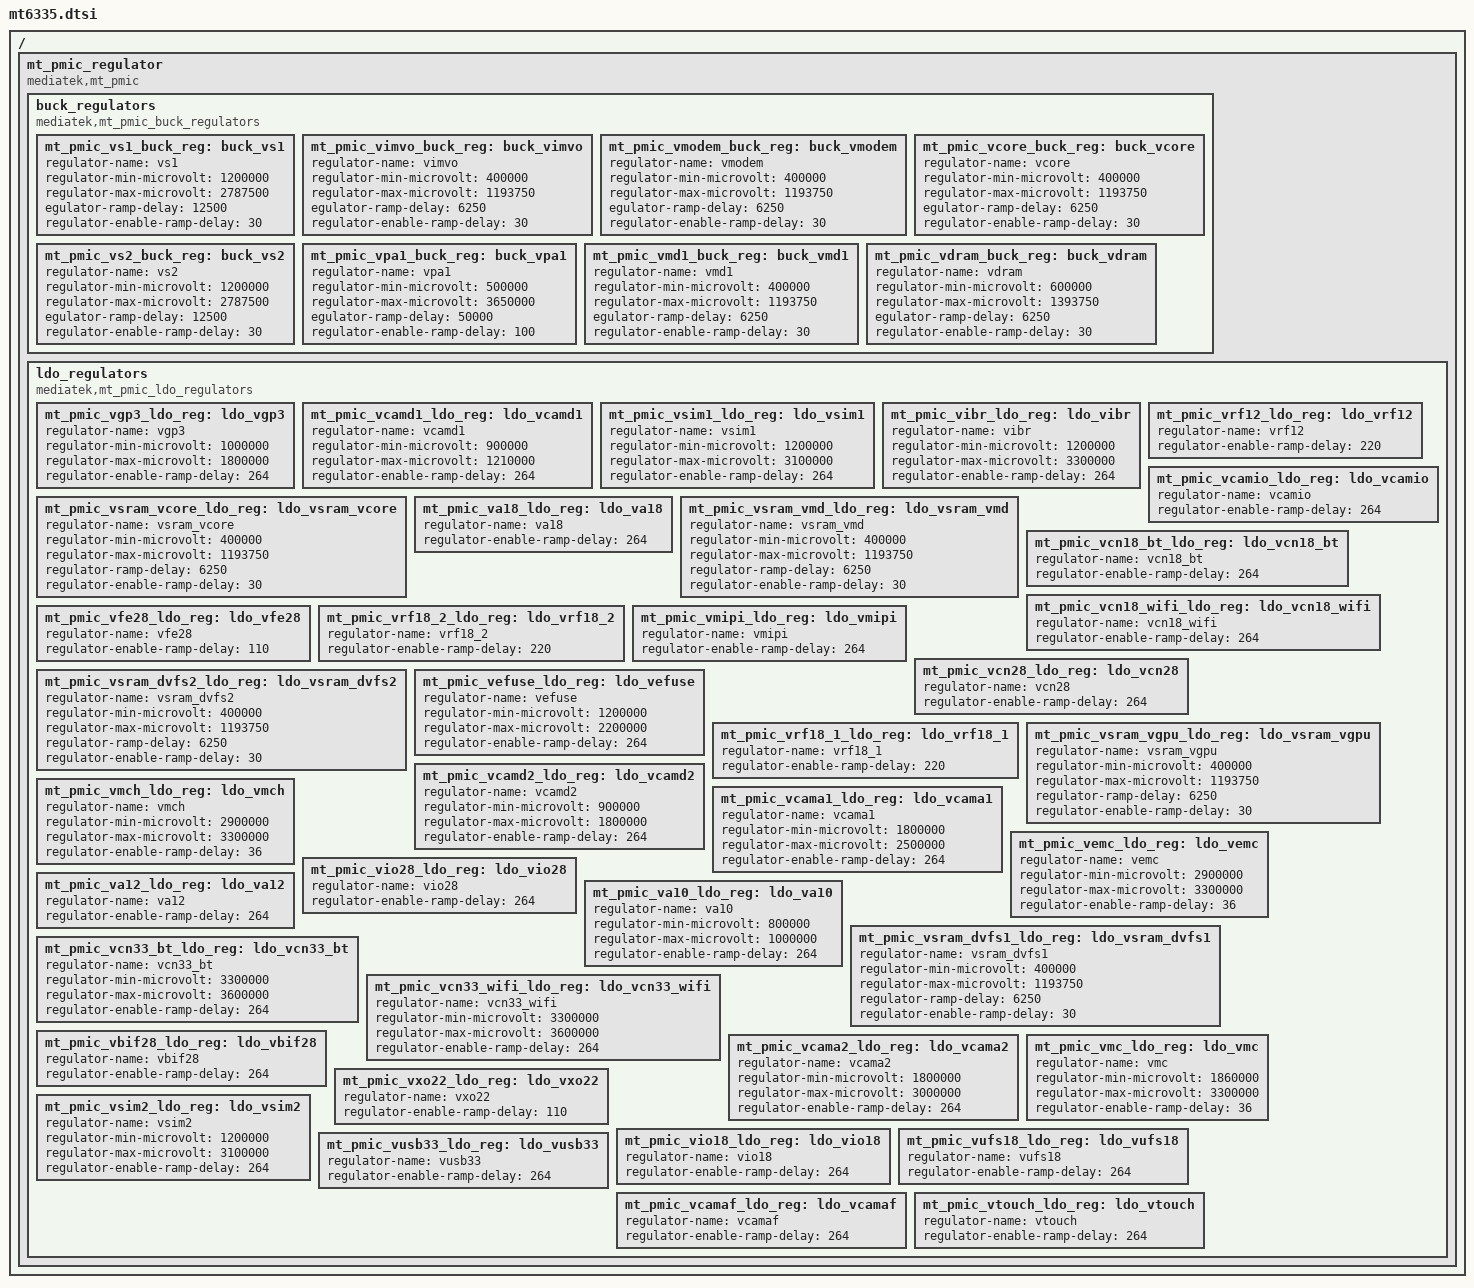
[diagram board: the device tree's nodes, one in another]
/ {
mt_pmic_regulator {
	compatible = "mediatek,mt_pmic";
	buck_regulators {
		compatible = "mediatek,mt_pmic_buck_regulators";
		mt_pmic_vs1_buck_reg: buck_vs1 {
			regulator-name = "vs1";
			regulator-min-microvolt = <1200000>;
			regulator-max-microvolt = <2787500>;
			egulator-ramp-delay = <12500>;
			regulator-enable-ramp-delay = <30>;
		};
		mt_pmic_vimvo_buck_reg: buck_vimvo {
			regulator-name = "vimvo";
			regulator-min-microvolt = <400000>;
			regulator-max-microvolt = <1193750>;
			egulator-ramp-delay = <6250>;
			regulator-enable-ramp-delay = <30>;
		};
		mt_pmic_vmodem_buck_reg: buck_vmodem {
			regulator-name = "vmodem";
			regulator-min-microvolt = <400000>;
			regulator-max-microvolt = <1193750>;
			egulator-ramp-delay = <6250>;
			regulator-enable-ramp-delay = <30>;
		};
		mt_pmic_vcore_buck_reg: buck_vcore {
			regulator-name = "vcore";
			regulator-min-microvolt = <400000>;
			regulator-max-microvolt = <1193750>;
			egulator-ramp-delay = <6250>;
			regulator-enable-ramp-delay = <30>;
		};
		mt_pmic_vs2_buck_reg: buck_vs2 {
			regulator-name = "vs2";
			regulator-min-microvolt = <1200000>;
			regulator-max-microvolt = <2787500>;
			egulator-ramp-delay = <12500>;
			regulator-enable-ramp-delay = <30>;
		};
		mt_pmic_vpa1_buck_reg: buck_vpa1 {
			regulator-name = "vpa1";
			regulator-min-microvolt = <500000>;
			regulator-max-microvolt = <3650000>;
			egulator-ramp-delay = <50000>;
			regulator-enable-ramp-delay = <100>;
		};
		mt_pmic_vmd1_buck_reg: buck_vmd1 {
			regulator-name = "vmd1";
			regulator-min-microvolt = <400000>;
			regulator-max-microvolt = <1193750>;
			egulator-ramp-delay = <6250>;
			regulator-enable-ramp-delay = <30>;
		};
		mt_pmic_vdram_buck_reg: buck_vdram {
			regulator-name = "vdram";
			regulator-min-microvolt = <600000>;
			regulator-max-microvolt = <1393750>;
			egulator-ramp-delay = <6250>;
			regulator-enable-ramp-delay = <30>;
		};
	};	/* End of buck_regulators */
	ldo_regulators {
		compatible = "mediatek,mt_pmic_ldo_regulators";
		mt_pmic_vgp3_ldo_reg: ldo_vgp3 {
			regulator-name = "vgp3";
			regulator-min-microvolt = <1000000>;
			regulator-max-microvolt = <1800000>;
			regulator-enable-ramp-delay = <264>;
		};
		mt_pmic_vcamd1_ldo_reg: ldo_vcamd1 {
			regulator-name = "vcamd1";
			regulator-min-microvolt = <900000>;
			regulator-max-microvolt = <1210000>;
			regulator-enable-ramp-delay = <264>;
		};
		mt_pmic_vsim1_ldo_reg: ldo_vsim1 {
			regulator-name = "vsim1";
			regulator-min-microvolt = <1200000>;
			regulator-max-microvolt = <3100000>;
			regulator-enable-ramp-delay = <264>;
		};
		mt_pmic_vibr_ldo_reg: ldo_vibr {
			regulator-name = "vibr";
			regulator-min-microvolt = <1200000>;
			regulator-max-microvolt = <3300000>;
			regulator-enable-ramp-delay = <264>;
		};
		mt_pmic_vrf12_ldo_reg: ldo_vrf12 {
			regulator-name = "vrf12";
			regulator-enable-ramp-delay = <220>;
		};
		mt_pmic_vsram_vcore_ldo_reg: ldo_vsram_vcore {
			regulator-name = "vsram_vcore";
			regulator-min-microvolt = <400000>;
			regulator-max-microvolt = <1193750>;
			regulator-ramp-delay = <6250>;
			regulator-enable-ramp-delay = <30>;
		};
		mt_pmic_vcamio_ldo_reg: ldo_vcamio {
			regulator-name = "vcamio";
			regulator-enable-ramp-delay = <264>;
		};
		mt_pmic_va18_ldo_reg: ldo_va18 {
			regulator-name = "va18";
			regulator-enable-ramp-delay = <264>;
		};
		mt_pmic_vsram_vmd_ldo_reg: ldo_vsram_vmd {
			regulator-name = "vsram_vmd";
			regulator-min-microvolt = <400000>;
			regulator-max-microvolt = <1193750>;
			regulator-ramp-delay = <6250>;
			regulator-enable-ramp-delay = <30>;
		};
		mt_pmic_vcn18_bt_ldo_reg: ldo_vcn18_bt {
			regulator-name = "vcn18_bt";
			regulator-enable-ramp-delay = <264>;
		};
		mt_pmic_vcn18_wifi_ldo_reg: ldo_vcn18_wifi {
			regulator-name = "vcn18_wifi";
			regulator-enable-ramp-delay = <264>;
		};
		mt_pmic_vfe28_ldo_reg: ldo_vfe28 {
			regulator-name = "vfe28";
			regulator-enable-ramp-delay = <110>;
		};
		mt_pmic_vrf18_2_ldo_reg: ldo_vrf18_2 {
			regulator-name = "vrf18_2";
			regulator-enable-ramp-delay = <220>;
		};
		mt_pmic_vmipi_ldo_reg: ldo_vmipi {
			regulator-name = "vmipi";
			regulator-enable-ramp-delay = <264>;
		};
		mt_pmic_vcn28_ldo_reg: ldo_vcn28 {
			regulator-name = "vcn28";
			regulator-enable-ramp-delay = <264>;
		};
		mt_pmic_vsram_dvfs2_ldo_reg: ldo_vsram_dvfs2 {
			regulator-name = "vsram_dvfs2";
			regulator-min-microvolt = <400000>;
			regulator-max-microvolt = <1193750>;
			regulator-ramp-delay = <6250>;
			regulator-enable-ramp-delay = <30>;
		};
		mt_pmic_vefuse_ldo_reg: ldo_vefuse {
			regulator-name = "vefuse";
			regulator-min-microvolt = <1200000>;
			regulator-max-microvolt = <2200000>;
			regulator-enable-ramp-delay = <264>;
		};
		mt_pmic_vrf18_1_ldo_reg: ldo_vrf18_1 {
			regulator-name = "vrf18_1";
			regulator-enable-ramp-delay = <220>;
		};
		mt_pmic_vsram_vgpu_ldo_reg: ldo_vsram_vgpu {
			regulator-name = "vsram_vgpu";
			regulator-min-microvolt = <400000>;
			regulator-max-microvolt = <1193750>;
			regulator-ramp-delay = <6250>;
			regulator-enable-ramp-delay = <30>;
		};
		mt_pmic_vcamd2_ldo_reg: ldo_vcamd2 {
			regulator-name = "vcamd2";
			regulator-min-microvolt = <900000>;
			regulator-max-microvolt = <1800000>;
			regulator-enable-ramp-delay = <264>;
		};
		mt_pmic_vmch_ldo_reg: ldo_vmch {
			regulator-name = "vmch";
			regulator-min-microvolt = <2900000>;
			regulator-max-microvolt = <3300000>;
			regulator-enable-ramp-delay = <36>;
		};
		mt_pmic_vcama1_ldo_reg: ldo_vcama1 {
			regulator-name = "vcama1";
			regulator-min-microvolt = <1800000>;
			regulator-max-microvolt = <2500000>;
			regulator-enable-ramp-delay = <264>;
		};
		mt_pmic_vemc_ldo_reg: ldo_vemc {
			regulator-name = "vemc";
			regulator-min-microvolt = <2900000>;
			regulator-max-microvolt = <3300000>;
			regulator-enable-ramp-delay = <36>;
		};
		mt_pmic_vio28_ldo_reg: ldo_vio28 {
			regulator-name = "vio28";
			regulator-enable-ramp-delay = <264>;
		};
		mt_pmic_va12_ldo_reg: ldo_va12 {
			regulator-name = "va12";
			regulator-enable-ramp-delay = <264>;
		};
		mt_pmic_va10_ldo_reg: ldo_va10 {
			regulator-name = "va10";
			regulator-min-microvolt = <800000>;
			regulator-max-microvolt = <1000000>;
			regulator-enable-ramp-delay = <264>;
		};
		mt_pmic_vsram_dvfs1_ldo_reg: ldo_vsram_dvfs1 {
			regulator-name = "vsram_dvfs1";
			regulator-min-microvolt = <400000>;
			regulator-max-microvolt = <1193750>;
			regulator-ramp-delay = <6250>;
			regulator-enable-ramp-delay = <30>;
		};
		mt_pmic_vcn33_bt_ldo_reg: ldo_vcn33_bt {
			regulator-name = "vcn33_bt";
			regulator-min-microvolt = <3300000>;
			regulator-max-microvolt = <3600000>;
			regulator-enable-ramp-delay = <264>;
		};
		mt_pmic_vcn33_wifi_ldo_reg: ldo_vcn33_wifi {
			regulator-name = "vcn33_wifi";
			regulator-min-microvolt = <3300000>;
			regulator-max-microvolt = <3600000>;
			regulator-enable-ramp-delay = <264>;
		};
		mt_pmic_vbif28_ldo_reg: ldo_vbif28 {
			regulator-name = "vbif28";
			regulator-enable-ramp-delay = <264>;
		};
		mt_pmic_vcama2_ldo_reg: ldo_vcama2 {
			regulator-name = "vcama2";
			regulator-min-microvolt = <1800000>;
			regulator-max-microvolt = <3000000>;
			regulator-enable-ramp-delay = <264>;
		};
		mt_pmic_vmc_ldo_reg: ldo_vmc {
			regulator-name = "vmc";
			regulator-min-microvolt = <1860000>;
			regulator-max-microvolt = <3300000>;
			regulator-enable-ramp-delay = <36>;
		};
		mt_pmic_vxo22_ldo_reg: ldo_vxo22 {
			regulator-name = "vxo22";
			regulator-enable-ramp-delay = <110>;
		};
		mt_pmic_vsim2_ldo_reg: ldo_vsim2 {
			regulator-name = "vsim2";
			regulator-min-microvolt = <1200000>;
			regulator-max-microvolt = <3100000>;
			regulator-enable-ramp-delay = <264>;
		};
		mt_pmic_vio18_ldo_reg: ldo_vio18 {
			regulator-name = "vio18";
			regulator-enable-ramp-delay = <264>;
		};
		mt_pmic_vufs18_ldo_reg: ldo_vufs18 {
			regulator-name = "vufs18";
			regulator-enable-ramp-delay = <264>;
		};
		mt_pmic_vusb33_ldo_reg: ldo_vusb33 {
			regulator-name = "vusb33";
			regulator-enable-ramp-delay = <264>;
		};
		mt_pmic_vcamaf_ldo_reg: ldo_vcamaf {
			regulator-name = "vcamaf";
			regulator-enable-ramp-delay = <264>;
		};
		mt_pmic_vtouch_ldo_reg: ldo_vtouch {
			regulator-name = "vtouch";
			regulator-enable-ramp-delay = <264>;
		};
	};	/* End of ldo_regulators */
};	/* End of mt_pmic_regulator */
};
